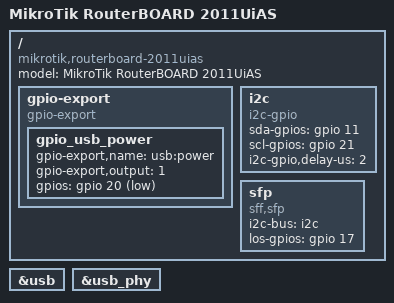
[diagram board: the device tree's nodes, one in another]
// SPDX-License-Identifier: GPL-2.0-or-later OR MIT

#include "ar9344_mikrotik_routerboard-2011.dtsi"

#include <dt-bindings/gpio/gpio.h>
#include <dt-bindings/input/input.h>

/ {
	compatible = "mikrotik,routerboard-2011uias", "qca,ar9344";
	model = "MikroTik RouterBOARD 2011UiAS";

	gpio-export {
		compatible = "gpio-export";

		gpio_usb_power {
			gpio-export,name = "usb:power";
			gpio-export,output = <1>;
			gpios = <&gpio 20 GPIO_ACTIVE_LOW>;
		};
	};

	i2c: i2c {
		compatible = "i2c-gpio";
		sda-gpios = <&gpio 11 (GPIO_ACTIVE_HIGH | GPIO_OPEN_DRAIN)>;
		scl-gpios = <&gpio 21 (GPIO_ACTIVE_HIGH | GPIO_OPEN_DRAIN)>;
		i2c-gpio,delay-us = <2>;
		#address-cells = <1>;
		#size-cells = <0>;
	};

	sfp: sfp {
		compatible = "sff,sfp";
		i2c-bus = <&i2c>;
		los-gpios = <&gpio 17 GPIO_ACTIVE_HIGH>;
		/*mod-def0-gpios = <&gpio __ GPIO_ACTIVE_HIGH>;
		tx-fault-gpios = <&gpio __ GPIO_ACTIVE_HIGH>;
		tx-disable-gpios = <&gpio __ GPIO_ACTIVE_HIGH>;*/
	};
};

&usb {
	status = "okay";
};

&usb_phy {
	status = "okay";
};
